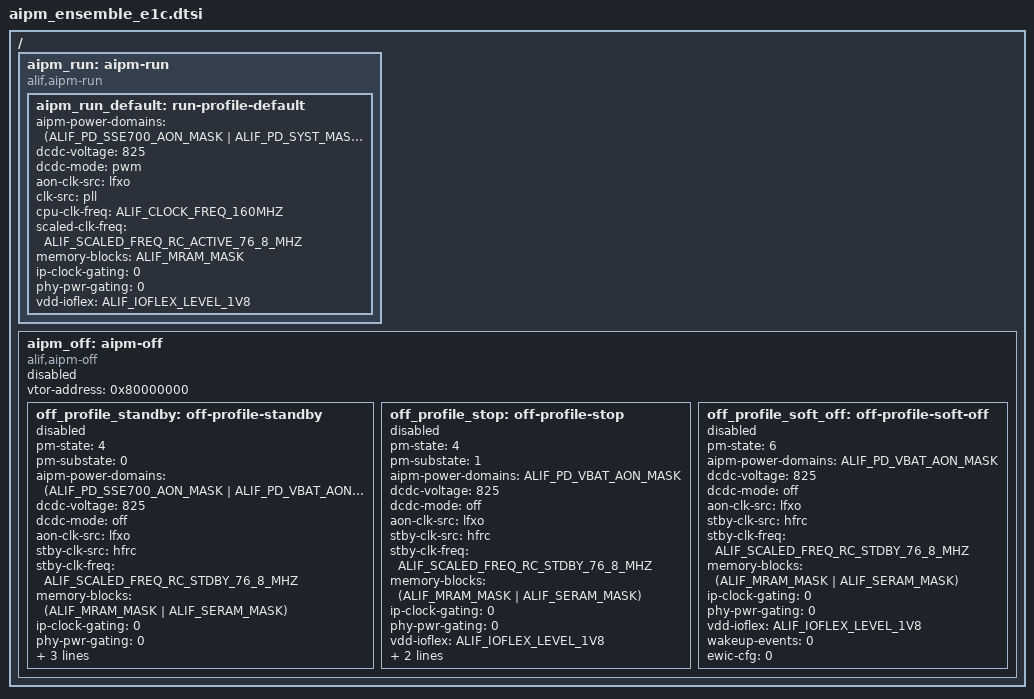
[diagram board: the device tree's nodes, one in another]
/* Copyright (c) 2026 Alif Semiconductor
 *
 * SPDX-License-Identifier: Apache-2.0
 */

/*
 * AIPM run/off profile defaults for Ensemble E1C SoC.
 *
 * E1C is HE-only, so cpu-clk-freq and vtor-address are included
 * directly (no separate HP/HE dtsi override needed).
 */

#include <dt-bindings/misc/alif_aipm_ensemble_e1c.h>

/ {
	aipm_run: aipm-run {
		compatible = "alif,aipm-run";
		status = "okay";

		aipm_run_default: run-profile-default {
			aipm-power-domains = <(ALIF_PD_SSE700_AON_MASK | ALIF_PD_SYST_MASK |
					       ALIF_PD_DBSS_MASK)>;
			dcdc-voltage    = <825>;
			dcdc-mode       = "pwm";
			aon-clk-src     = "lfxo";
			clk-src         = "pll";
			cpu-clk-freq    = <ALIF_CLOCK_FREQ_160MHZ>;
			scaled-clk-freq = <ALIF_SCALED_FREQ_RC_ACTIVE_76_8_MHZ>;
			memory-blocks   = <ALIF_MRAM_MASK>;
			ip-clock-gating = <0>;
			phy-pwr-gating  = <0>;
			vdd-ioflex      = <ALIF_IOFLEX_LEVEL_1V8>;
		};
	};
};

/ {
	aipm_off: aipm-off {
		compatible = "alif,aipm-off";
		status = "disabled";
		vtor-address = <0x80000000>;

		off_profile_standby: off-profile-standby {
			status             = "disabled";
			pm-state           = <4>; /* PM_STATE_SUSPEND_TO_RAM */
			pm-substate        = <0>;
			aipm-power-domains = <(ALIF_PD_SSE700_AON_MASK | ALIF_PD_VBAT_AON_MASK)>;
			dcdc-voltage       = <825>;
			dcdc-mode          = "off";
			aon-clk-src        = "lfxo";
			stby-clk-src       = "hfrc";
			stby-clk-freq      = <ALIF_SCALED_FREQ_RC_STDBY_76_8_MHZ>;
			memory-blocks      = <(ALIF_MRAM_MASK | ALIF_SERAM_MASK)>;
			ip-clock-gating    = <0>;
			phy-pwr-gating     = <0>;
			vdd-ioflex         = <ALIF_IOFLEX_LEVEL_1V8>;
			wakeup-events      = <0>;
			ewic-cfg           = <0>;
		};

		off_profile_stop: off-profile-stop {
			status             = "disabled";
			pm-state           = <4>; /* PM_STATE_SUSPEND_TO_RAM */
			pm-substate        = <1>;
			aipm-power-domains = <ALIF_PD_VBAT_AON_MASK>;
			dcdc-voltage       = <825>;
			dcdc-mode          = "off";
			aon-clk-src        = "lfxo";
			stby-clk-src       = "hfrc";
			stby-clk-freq      = <ALIF_SCALED_FREQ_RC_STDBY_76_8_MHZ>;
			memory-blocks      = <(ALIF_MRAM_MASK | ALIF_SERAM_MASK)>;
			ip-clock-gating    = <0>;
			phy-pwr-gating     = <0>;
			vdd-ioflex         = <ALIF_IOFLEX_LEVEL_1V8>;
			wakeup-events      = <0>;
			ewic-cfg           = <0>;
		};

		off_profile_soft_off: off-profile-soft-off {
			status             = "disabled";
			pm-state           = <6>; /* PM_STATE_SOFT_OFF */
			aipm-power-domains = <ALIF_PD_VBAT_AON_MASK>;
			dcdc-voltage       = <825>;
			dcdc-mode          = "off";
			aon-clk-src        = "lfxo";
			stby-clk-src       = "hfrc";
			stby-clk-freq      = <ALIF_SCALED_FREQ_RC_STDBY_76_8_MHZ>;
			memory-blocks      = <(ALIF_MRAM_MASK | ALIF_SERAM_MASK)>;
			ip-clock-gating    = <0>;
			phy-pwr-gating     = <0>;
			vdd-ioflex         = <ALIF_IOFLEX_LEVEL_1V8>;
			wakeup-events      = <0>;
			ewic-cfg           = <0>;
		};
	};
};
